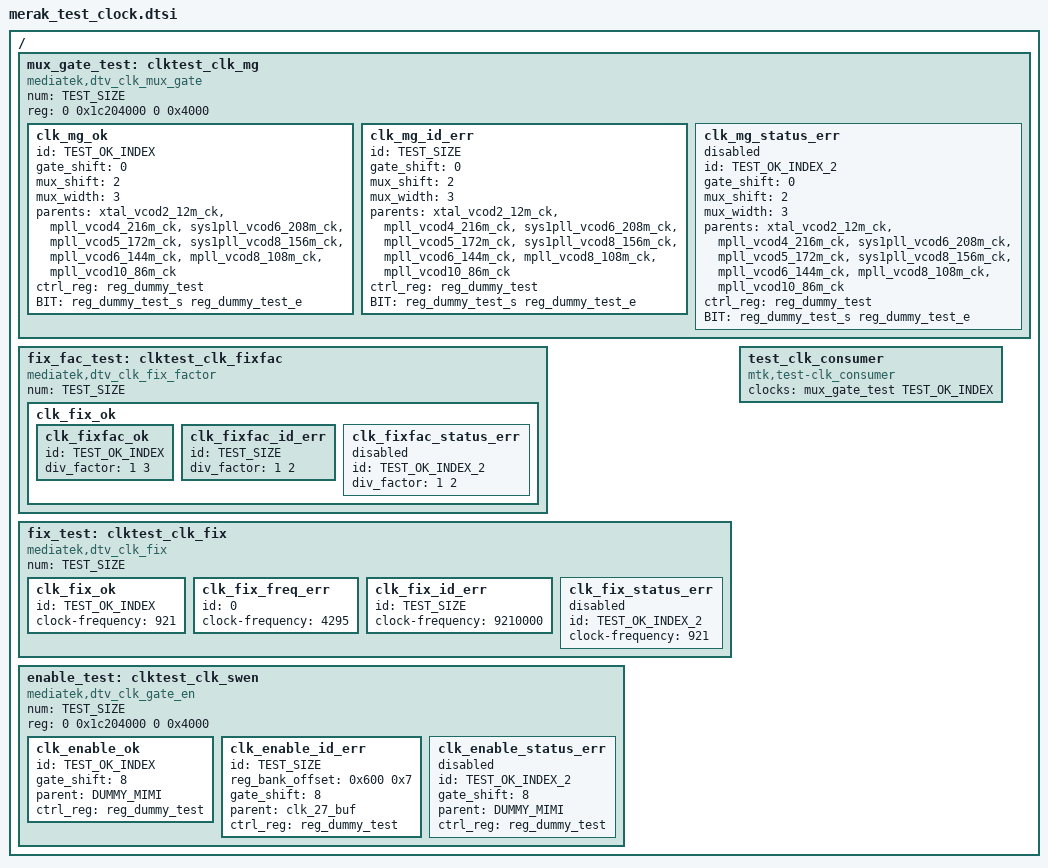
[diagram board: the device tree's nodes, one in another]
// SPDX-License-Identifier: (GPL-2.0 OR BSD-3-Clause)
/*
 * Copyright (c) 2020 MediaTek Inc.
 */

#define TEST_SIZE 4
#define TEST_OK_INDEX (TEST_SIZE-1)
#define TEST_OK_INDEX_2 (TEST_SIZE-2)

#define reg_dummy_test		0x1FFC
#define reg_dummy_test_s	0
#define reg_dummy_test_e	15
/ {

	mux_gate_test: clktest_clk_mg {
		#clock-cells = <1>;
		compatible = "mediatek,dtv_clk_mux_gate";
		num = <TEST_SIZE>;
		reg = <0 0x1c204000 0 0x4000>;

		clk_mg_ok {
			id = <TEST_OK_INDEX>;
			gate_shift = <0>; /* --> start_bit of gate conctrol */
			mux_shift = <2>; /* --> start bit of mux control */
			mux_width = <3>; /* --> bit number of mux control */
			parents = "xtal_vcod2_12m_ck","mpll_vcod4_216m_ck","sys1pll_vcod6_208m_ck",
				"mpll_vcod5_172m_ck","sys1pll_vcod8_156m_ck","mpll_vcod6_144m_ck",
				"mpll_vcod8_108m_ck","mpll_vcod10_86m_ck";
			ctrl_reg = <reg_dummy_test>;
			BIT = <reg_dummy_test_s reg_dummy_test_e>; /* control bit 0 to 15 */
		};
		clk_mg_id_err {
			id = <TEST_SIZE>;
			gate_shift = <0>; /* --> start_bit of gate conctrol */
			mux_shift = <2>; /* --> start bit of mux control */
			mux_width = <3>; /* --> bit number of mux control */
			parents = "xtal_vcod2_12m_ck","mpll_vcod4_216m_ck","sys1pll_vcod6_208m_ck",
				"mpll_vcod5_172m_ck","sys1pll_vcod8_156m_ck","mpll_vcod6_144m_ck",
				"mpll_vcod8_108m_ck","mpll_vcod10_86m_ck";
			ctrl_reg = <reg_dummy_test>;
			BIT = <reg_dummy_test_s reg_dummy_test_e>; /* control bit 0 to 15 */
		};
		clk_mg_status_err {
			id = <TEST_OK_INDEX_2>;
			gate_shift = <0>; /* --> start_bit of gate conctrol */
			mux_shift = <2>; /* --> start bit of mux control */
			mux_width = <3>; /* --> bit number of mux control */
			parents = "xtal_vcod2_12m_ck","mpll_vcod4_216m_ck","sys1pll_vcod6_208m_ck",
				"mpll_vcod5_172m_ck","sys1pll_vcod8_156m_ck","mpll_vcod6_144m_ck",
				"mpll_vcod8_108m_ck","mpll_vcod10_86m_ck";
			ctrl_reg = <reg_dummy_test>;
			BIT = <reg_dummy_test_s reg_dummy_test_e>; /* control bit 0 to 15 */
			status = "disabled";
		};

	};

	fix_fac_test: clktest_clk_fixfac {
		#clock-cells = <1>;
		compatible = "mediatek,dtv_clk_fix_factor";
		num = <TEST_SIZE>;
		clk_fix_ok {
			clk_fixfac_ok {
				id = <TEST_OK_INDEX>;
				div_factor = <1 3>;
			};
			clk_fixfac_id_err {
				id = <TEST_SIZE>;
				div_factor = <1 2>;
			};
			clk_fixfac_status_err {
				id = <TEST_OK_INDEX_2>;
				div_factor = <1 2>;
				status = "disabled";
			};
		};
	};

	fix_test: clktest_clk_fix {
		#clock-cells = <1>;
		compatible = "mediatek,dtv_clk_fix";
		num = <TEST_SIZE>;
		clk_fix_ok {
			id = <TEST_OK_INDEX>;
			clock-frequency = <921>;
		};
		clk_fix_freq_err {
			id = <0>;
			clock-frequency = <4295>; /* (2^32-1)/MHZ */
		};
		clk_fix_id_err {
			id = <TEST_SIZE>;
			clock-frequency = <9210000>;
		};
		clk_fix_status_err {
			id = <TEST_OK_INDEX_2>;
			clock-frequency = <921>;
			status = "disabled";
		};

	};

	enable_test: clktest_clk_swen {
		#clock-cells = <1>;
		compatible = "mediatek,dtv_clk_gate_en";
		num = <TEST_SIZE>;
		reg = <0 0x1c204000 0 0x4000>;

		clk_enable_ok {
			id = <TEST_OK_INDEX>;
			gate_shift = <8>;
			parent = "DUMMY_MIMI";
			ctrl_reg = <reg_dummy_test>;
		};
		clk_enable_id_err {
			id = <TEST_SIZE>;
			reg_bank_offset = <0x600 0x7>; /* bank: 0x6, 16-bit addr : 0x9 */
			gate_shift = <8>;
			parent = "clk_27_buf";
			ctrl_reg = <reg_dummy_test>;
		};
		clk_enable_status_err {
			id = <TEST_OK_INDEX_2>;
			gate_shift = <8>;
			parent = "DUMMY_MIMI";
			ctrl_reg = <reg_dummy_test>;
			status = "disabled";
		};
	};

	test_clk_consumer {
		compatible = "mtk,test-clk_consumer";
		clocks = <&mux_gate_test TEST_OK_INDEX>;
		clock-names = "ooxx";
	};

};
